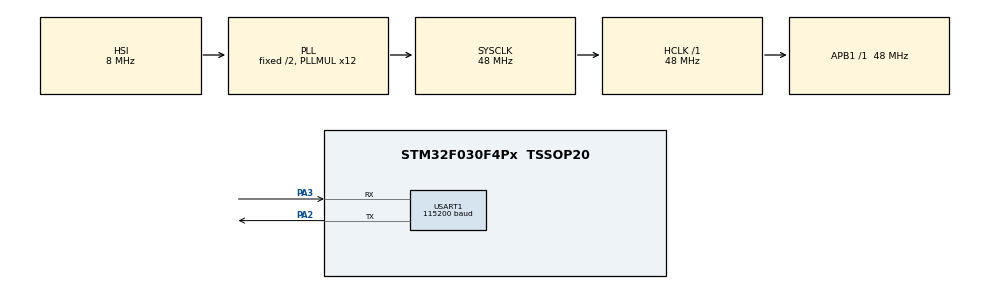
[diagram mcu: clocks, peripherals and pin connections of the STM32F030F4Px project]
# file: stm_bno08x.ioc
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Dma.Request0=USART1_RX
Dma.USART1_RX.0.Direction=DMA_PERIPH_TO_MEMORY
Dma.USART1_RX.0.Instance=DMA1_Channel3
Dma.USART1_RX.0.MemDataAlignment=DMA_MDATAALIGN_BYTE
Dma.USART1_RX.0.MemInc=DMA_MINC_ENABLE
Dma.USART1_RX.0.Mode=DMA_CIRCULAR
Dma.USART1_RX.0.PeriphDataAlignment=DMA_PDATAALIGN_BYTE
Dma.USART1_RX.0.PeriphInc=DMA_PINC_DISABLE
Dma.USART1_RX.0.Priority=DMA_PRIORITY_LOW
Mcu.Family=STM32F0
Mcu.Name=STM32F030F4Px
Mcu.Package=TSSOP20
NVIC.DMA1_Channel2_3_IRQn=true\:0\:0\:false\:false\:true\:false\:true\:true
PA13.Mode=Serial_Wire
PA13.Signal=SYS_SWDIO
PA14.Mode=Serial_Wire
PA14.Signal=SYS_SWCLK
PA2.Mode=Asynchronous
PA2.Signal=USART1_TX
PA3.Mode=Asynchronous
PA3.Signal=USART1_RX
ProjectManager.HeapSize=0x200
ProjectManager.StackSize=0x400
ProjectManager.TargetToolchain=Makefile
RCC.AHBFreq_Value=48000000
RCC.APB1Freq_Value=48000000
RCC.APB1TimFreq_Value=48000000
RCC.HCLKFreq_Value=48000000
RCC.PLLMUL=RCC_PLL_MUL12
RCC.SYSCLKFreq_VALUE=48000000
RCC.SYSCLKSource=RCC_SYSCLKSOURCE_PLLCLK
USART1.BaudRate=115200
USART1.VirtualMode-Asynchronous=VM_ASYNC
board=custom

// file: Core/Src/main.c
/* USER CODE BEGIN Header */
/**
 ******************************************************************************
 * @file           : main.c
 * @brief          : Main program body
 ******************************************************************************
 * @attention
 *
 * Copyright (c) 2023 STMicroelectronics.
 * All rights reserved.
 *
 * This software is licensed under terms that can be found in the LICENSE file
 * in the root directory of this software component.
 * If no LICENSE file comes with this software, it is provided AS-IS.
 *
 ******************************************************************************
 */
/* USER CODE END Header */
#include "main.h"
#include "dma.h"
#include "usart.h"
#include "gpio.h"

/* USER CODE BEGIN Includes */
#include "bno08x_uart_rvc.h"
/* USER CODE END Includes */

/* USER CODE BEGIN PV */
uint8_t buffer[BUFFER_LENGTH];
uint8_t sorted_buffer[BUFFER_LENGTH] = {0};
BNO08x_t bno;
/* USER CODE END PV */

void SystemClock_Config(void);

int main(void)
{

  /* MCU Configuration--------------------------------------------------------*/

  /* Reset of all peripherals, Initializes the Flash interface and the Systick. */
  HAL_Init();

  /* Configure the system clock */
  SystemClock_Config();

  /* Initialize all configured peripherals */
  MX_GPIO_Init();
  MX_DMA_Init();
  MX_USART1_UART_Init();
  /* USER CODE BEGIN 2 */
  HAL_UART_Receive_DMA(&huart1, buffer, BUFFER_LENGTH);
  /* USER CODE END 2 */

  /* Infinite loop */
  /* USER CODE BEGIN WHILE */
  while (1)
  {
    HAL_Delay(100);
    /* USER CODE END WHILE */

  }
}

void SystemClock_Config(void)
{
  RCC_OscInitTypeDef RCC_OscInitStruct = {0};
  RCC_ClkInitTypeDef RCC_ClkInitStruct = {0};
  RCC_PeriphCLKInitTypeDef PeriphClkInit = {0};

  /** Initializes the RCC Oscillators according to the specified parameters
   * in the RCC_OscInitTypeDef structure.
   */
  RCC_OscInitStruct.OscillatorType = RCC_OSCILLATORTYPE_HSI;
  RCC_OscInitStruct.HSIState = RCC_HSI_ON;
  RCC_OscInitStruct.HSICalibrationValue = RCC_HSICALIBRATION_DEFAULT;
  RCC_OscInitStruct.PLL.PLLState = RCC_PLL_ON;
  RCC_OscInitStruct.PLL.PLLSource = RCC_PLLSOURCE_HSI;
  RCC_OscInitStruct.PLL.PLLMUL = RCC_PLL_MUL12;
  RCC_OscInitStruct.PLL.PREDIV = RCC_PREDIV_DIV1;
  if (HAL_RCC_OscConfig(&RCC_OscInitStruct) != HAL_OK)
  {
    Error_Handler();
  }

  /** Initializes the CPU, AHB and APB buses clocks
   */
  RCC_ClkInitStruct.ClockType = RCC_CLOCKTYPE_HCLK | RCC_CLOCKTYPE_SYSCLK | RCC_CLOCKTYPE_PCLK1;
  RCC_ClkInitStruct.SYSCLKSource = RCC_SYSCLKSOURCE_PLLCLK;
  RCC_ClkInitStruct.AHBCLKDivider = RCC_SYSCLK_DIV1;
  RCC_ClkInitStruct.APB1CLKDivider = RCC_HCLK_DIV1;

  if (HAL_RCC_ClockConfig(&RCC_ClkInitStruct, FLASH_LATENCY_1) != HAL_OK)
  {
    Error_Handler();
  }
  PeriphClkInit.PeriphClockSelection = RCC_PERIPHCLK_USART1;
  PeriphClkInit.Usart1ClockSelection = RCC_USART1CLKSOURCE_PCLK1;
  if (HAL_RCCEx_PeriphCLKConfig(&PeriphClkInit) != HAL_OK)
  {
    Error_Handler();
  }
}

/* USER CODE BEGIN 4 */
void HAL_UART_RxCpltCallback(UART_HandleTypeDef *huart)
{
  if (huart->Instance == USART1)
  {
    sort_buffer(buffer, sorted_buffer);
    update_bno(&bno, sorted_buffer);
  }
}
/* USER CODE END 4 */

void Error_Handler(void)
{
  __disable_irq();
  while (1)
  {
  }
}
